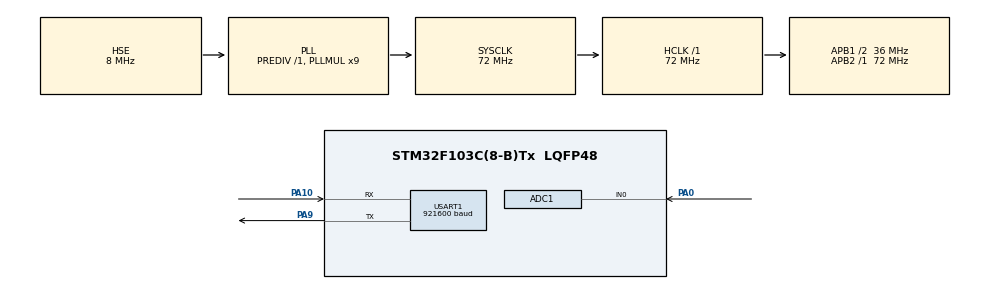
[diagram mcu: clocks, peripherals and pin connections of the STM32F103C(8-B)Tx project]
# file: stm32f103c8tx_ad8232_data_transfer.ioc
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ADC1.Channel-0\#ChannelRegularConversion=ADC_CHANNEL_0
ADC1.ContinuousConvMode=ENABLE
ADC1.ExternalTrigConv=ADC_SOFTWARE_START
ADC1.NbrOfConversionFlag=1
ADC1.Rank-0\#ChannelRegularConversion=1
ADC1.SamplingTime-0\#ChannelRegularConversion=ADC_SAMPLETIME_239CYCLES_5
ADC1.master=1
Dma.ADC1.0.Direction=DMA_PERIPH_TO_MEMORY
Dma.ADC1.0.Instance=DMA1_Channel1
Dma.ADC1.0.MemDataAlignment=DMA_MDATAALIGN_HALFWORD
Dma.ADC1.0.MemInc=DMA_MINC_ENABLE
Dma.ADC1.0.Mode=DMA_CIRCULAR
Dma.ADC1.0.PeriphDataAlignment=DMA_PDATAALIGN_HALFWORD
Dma.ADC1.0.PeriphInc=DMA_PINC_DISABLE
Dma.ADC1.0.Priority=DMA_PRIORITY_HIGH
Dma.Request0=ADC1
Dma.Request1=USART1_TX
Dma.USART1_TX.1.Direction=DMA_MEMORY_TO_PERIPH
Dma.USART1_TX.1.Instance=DMA1_Channel4
Dma.USART1_TX.1.MemDataAlignment=DMA_MDATAALIGN_BYTE
Dma.USART1_TX.1.MemInc=DMA_MINC_ENABLE
Dma.USART1_TX.1.Mode=DMA_CIRCULAR
Dma.USART1_TX.1.PeriphDataAlignment=DMA_PDATAALIGN_BYTE
Dma.USART1_TX.1.PeriphInc=DMA_PINC_DISABLE
Dma.USART1_TX.1.Priority=DMA_PRIORITY_HIGH
Mcu.Family=STM32F1
Mcu.Name=STM32F103C(8-B)Tx
Mcu.Package=LQFP48
NVIC.DMA1_Channel1_IRQn=true\:0\:0\:false\:false\:true\:false\:true\:true
NVIC.DMA1_Channel4_IRQn=true\:0\:0\:false\:false\:true\:false\:true\:true
NVIC.PriorityGroup=NVIC_PRIORITYGROUP_4
NVIC.USART1_IRQn=true\:0\:0\:false\:false\:true\:true\:true\:true
PA0-WKUP.Signal=ADCx_IN0
PA10.Mode=Asynchronous
PA10.Signal=USART1_RX
PA13.Mode=Serial_Wire
PA13.Signal=SYS_JTMS-SWDIO
PA14.Mode=Serial_Wire
PA14.Signal=SYS_JTCK-SWCLK
PA9.Mode=Asynchronous
PA9.Signal=USART1_TX
PD0-OSC_IN.Mode=HSE-External-Oscillator
PD0-OSC_IN.Signal=RCC_OSC_IN
PD1-OSC_OUT.Mode=HSE-External-Oscillator
PD1-OSC_OUT.Signal=RCC_OSC_OUT
ProjectManager.HeapSize=0x200
ProjectManager.StackSize=0x400
ProjectManager.TargetToolchain=MDK-ARM V5.27
RCC.ADCPresc=RCC_ADCPCLK2_DIV6
RCC.AHBFreq_Value=72000000
RCC.APB1CLKDivider=RCC_HCLK_DIV2
RCC.APB1Freq_Value=36000000
RCC.APB1TimFreq_Value=72000000
RCC.APB2Freq_Value=72000000
RCC.APB2TimFreq_Value=72000000
RCC.HCLKFreq_Value=72000000
RCC.PLLMUL=RCC_PLL_MUL9
RCC.PLLSourceVirtual=RCC_PLLSOURCE_HSE
RCC.SYSCLKFreq_VALUE=72000000
RCC.SYSCLKSource=RCC_SYSCLKSOURCE_PLLCLK
RCC.USBFreq_Value=72000000
SH.ADCx_IN0.0=ADC1_IN0,IN0
USART1.BaudRate=921600
USART1.VirtualMode=VM_ASYNC
VP_IWDG_VS_IWDG.Mode=IWDG_Activate
board=custom

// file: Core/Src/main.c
/* USER CODE BEGIN Header */
/**
 ******************************************************************************
 * @file           : main.c
 * @brief          : Main program body
 ******************************************************************************
 * @attention
 *
 * Copyright (c) 2024 STMicroelectronics.
 * All rights reserved.
 *
 * This software is licensed under terms that can be found in the LICENSE file
 * in the root directory of this software component.
 * If no LICENSE file comes with this software, it is provided AS-IS.
 *
 ******************************************************************************
 */
/* USER CODE END Header */
#include "main.h"
#include "adc.h"
#include "dma.h"
#include "iwdg.h"
#include "usart.h"
#include "gpio.h"

/* USER CODE BEGIN Includes */
#include <stdio.h>
/* USER CODE END Includes */

/* USER CODE BEGIN PV */
uint32_t sample;
uint8_t TxBuffer[4];
uint8_t RxBuffer[8];
/* USER CODE END PV */

void SystemClock_Config(void);

int main(void)
{

  /* MCU Configuration--------------------------------------------------------*/

  /* Reset of all peripherals, Initializes the Flash interface and the Systick. */
  HAL_Init();

  /* Configure the system clock */
  SystemClock_Config();

  /* Initialize all configured peripherals */
  MX_GPIO_Init();
  MX_DMA_Init();
  MX_ADC1_Init();
  MX_USART1_UART_Init();
  MX_IWDG_Init();
  /* USER CODE BEGIN 2 */
  HAL_ADCEx_Calibration_Start(&hadc1);
  HAL_ADC_Start_DMA(&hadc1, (uint32_t *)&sample, 1);
  // HAL_UART_Receive_IT(&huart1, (uint8_t *)RxBuffer, 8);
  /* USER CODE END 2 */

  /* Infinite loop */
  /* USER CODE BEGIN WHILE */
  while (1)
  {
    HAL_IWDG_Refresh(&hiwdg);
    TxBuffer[0] = 0xEC;
    TxBuffer[1] = (uint8_t)(sample >> 8);
    TxBuffer[2] = (uint8_t)(sample & 0xff);
    TxBuffer[3] = (TxBuffer[1]) ^ (TxBuffer[2]);
    HAL_UART_Transmit(&huart1, (uint8_t *)TxBuffer, 4, 100);
    HAL_Delay(100);
    /* USER CODE END WHILE */

  }
}

void SystemClock_Config(void)
{
  RCC_OscInitTypeDef RCC_OscInitStruct = {0};
  RCC_ClkInitTypeDef RCC_ClkInitStruct = {0};
  RCC_PeriphCLKInitTypeDef PeriphClkInit = {0};

  /** Initializes the RCC Oscillators according to the specified parameters
  * in the RCC_OscInitTypeDef structure.
  */
  RCC_OscInitStruct.OscillatorType = RCC_OSCILLATORTYPE_LSI|RCC_OSCILLATORTYPE_HSE;
  RCC_OscInitStruct.HSEState = RCC_HSE_ON;
  RCC_OscInitStruct.HSEPredivValue = RCC_HSE_PREDIV_DIV1;
  RCC_OscInitStruct.HSIState = RCC_HSI_ON;
  RCC_OscInitStruct.LSIState = RCC_LSI_ON;
  RCC_OscInitStruct.PLL.PLLState = RCC_PLL_ON;
  RCC_OscInitStruct.PLL.PLLSource = RCC_PLLSOURCE_HSE;
  RCC_OscInitStruct.PLL.PLLMUL = RCC_PLL_MUL9;
  if (HAL_RCC_OscConfig(&RCC_OscInitStruct) != HAL_OK)
  {
    Error_Handler();
  }

  /** Initializes the CPU, AHB and APB buses clocks
  */
  RCC_ClkInitStruct.ClockType = RCC_CLOCKTYPE_HCLK|RCC_CLOCKTYPE_SYSCLK
                              |RCC_CLOCKTYPE_PCLK1|RCC_CLOCKTYPE_PCLK2;
  RCC_ClkInitStruct.SYSCLKSource = RCC_SYSCLKSOURCE_PLLCLK;
  RCC_ClkInitStruct.AHBCLKDivider = RCC_SYSCLK_DIV1;
  RCC_ClkInitStruct.APB1CLKDivider = RCC_HCLK_DIV2;
  RCC_ClkInitStruct.APB2CLKDivider = RCC_HCLK_DIV1;

  if (HAL_RCC_ClockConfig(&RCC_ClkInitStruct, FLASH_LATENCY_2) != HAL_OK)
  {
    Error_Handler();
  }
  PeriphClkInit.PeriphClockSelection = RCC_PERIPHCLK_ADC;
  PeriphClkInit.AdcClockSelection = RCC_ADCPCLK2_DIV6;
  if (HAL_RCCEx_PeriphCLKConfig(&PeriphClkInit) != HAL_OK)
  {
    Error_Handler();
  }
}

void Error_Handler(void)
{
  __disable_irq();
  while (1)
  {
  }
}
